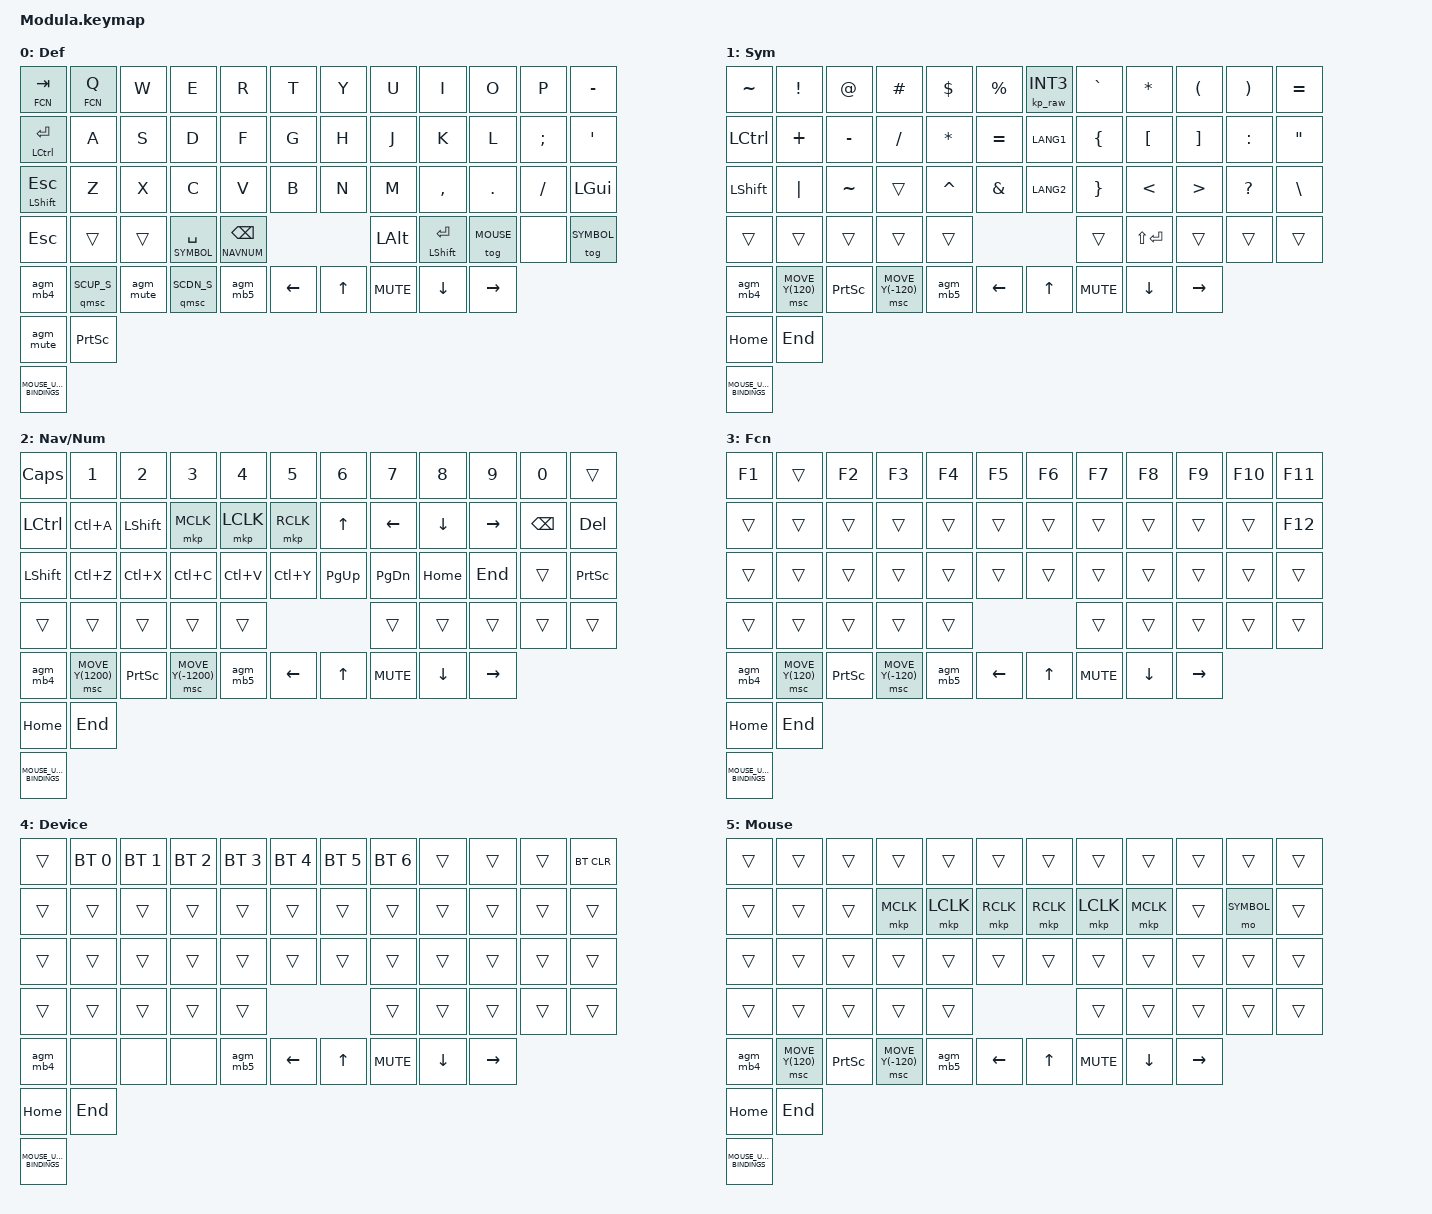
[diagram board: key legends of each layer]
#include <behaviors.dtsi>
#include <behaviors/jp.dtsi>
#include <behaviors/quick_scroll.dtsi>
#include <dt-bindings/zmk/bt.h>
#include <dt-bindings/zmk/keys.h>
#include <dt-bindings/zmk/pointing.h>
#include <dt-bindings/zmk/outputs.h>

#ifdef MODULA_MOUSE_UNIT
#define MODULE_ENCODER_BINDING &mouse_scrl
#define MOUSE_UNIT_BINDINGS &mkp LCLK &mkp RCLK
#else
#define MODULE_ENCODER_BINDING &bri_alt_gui
#define MOUSE_UNIT_BINDINGS
#endif

#define DEFAULT 0
#define SYMBOL 1
#define NAVNUM 2
#define FCN 3
#define DEVICE 4
#define MOUSE 5
#define SCUP_S MOVE_Y(120)
#define SCUP_F MOVE_Y(1200)
#define SCDN_S MOVE_Y(-120)
#define SCDN_F MOVE_Y(-1200)

&mt {
    flavor = "hold-preferred";
};

&lt {
    flavor = "hold-preferred";
};

&qmsc {
    double-tap-ms = <100>;
};

// &msc { 
//     delay-ms = <0>;
//     trigger-period-ms = <100>; // default:16
//     x-input-code = <INPUT_REL_HWHEEL>;
//     y-input-code = <INPUT_REL_WHEEL>;
//     time-to-max-speed-ms = <300>;
//     acceleration-exponent = <0>;
// };

/ {

    // msc_input_listener: msch_input_listener {
    //     compatible = "zmk,input-listener";
    //     device = <&msch>;
    //     // input-processors = 
    // };

    conditional_layers {
        compatible = "zmk,conditional-layers";
        device_layer {
            if-layers = <SYMBOL NAVNUM>;
            then-layer = <DEVICE>;
        };
    };

    combos{
    };

    behaviors {
        msch: msc-hold {
            compatible = "zmk,behavior-input-two-axis";
            #binding-cells = <1>;
            x-input-code = <INPUT_REL_HWHEEL>;
            y-input-code = <INPUT_REL_WHEEL>;
            time-to-max-speed-ms = <300>;
            acceleration-exponent = <0>;
        };
        msc_dt: msc-double-tap {
            compatible = "zmk,behavior-hold-tap";
            #binding-cells = <2>;
            flavor = "hold-preferred";
            tapping-term-ms = <100>;
            quick-tap-ms = <300>;
            bindings = <&msc>, <&msc>;
        };
        // Hold-Tap
        plt: positional_layer_tap {
            compatible = "zmk,behavior-hold-tap";
            #binding-cells = <2>;
            flavor = "hold-preferred";
            tapping-term-ms = <1000>;
            quick-tap-ms = <200>;
            bindings = <&mo>, <&kp>;
            hold-trigger-key-positions = <0>;
        };
        mth: mt-hold-while-undecided {
            compatible = "zmk,behavior-hold-tap";
            #binding-cells = <2>;
            flavor = "hold-preferred";
            hold-while-undecided;
            tapping-term-ms = <200>;
            bindings = <&kp>, <&kp>;
        };
        lth: lt-hold-while-undecided {
            compatible = "zmk,behavior-hold-tap";
            #binding-cells = <2>;
            flavor = "hold-preferred";
            hold-while-undecided;
            tapping-term-ms = <200>;
            bindings = <&mo>, <&kp>;
        };
        mtt: mt-tap-preferred {
            compatible = "zmk,behavior-hold-tap";
            #binding-cells = <2>;
            tapping-term-ms = <150>;
            quick-tap-ms = <0>;
            flavor = "tap-preferred";
            bindings = <&kp>, <&kp>;
        };
        ltt: lt-tap-preferred {
            compatible = "zmk,behavior-hold-tap";
            #binding-cells = <2>;
            flavor = "tap-preferred";
            tapping-term-ms = <200>;
            bindings = <&mo>, <&kp>;
        };
        // Encoders
        mouse_scrl: mouse_wheel_scrl {
            compatible = "zmk,behavior-sensor-rotate";
            #sensor-binding-cells = <0>;
            bindings = <&msc MOVE_UP>, <&msc MOVE_DOWN>;
            tap-ms = <20>;
        };
        vol_up_down: volume-up-down {
            compatible = "zmk,behavior-sensor-rotate";
            #sensor-binding-cells = <0>;
            bindings = <&kp C_VOL_UP>, <&kp C_VOL_DN>;
        };
        bri_up_down: brightness-up-down {
            compatible = "zmk,behavior-sensor-rotate";
            #sensor-binding-cells = <0>; 
            bindings = <&kp C_BRI_INC>, <&kp C_BRI_DEC>;
        };
        agm_mute: alt-gui-mute {
            compatible = "modula,behavior-alt-gui-morph";
            #binding-cells = <0>;
            bindings = <&kp C_MUTE>, <&kp LC(TAB)>, <&kp 0>;
        };
        agm_vol_up: alt-gui-volume-up {
            compatible = "modula,behavior-alt-gui-morph";
            #binding-cells = <0>;
            bindings = <&kp C_VOL_UP>, <&kp TAB>, <&kp RIGHT>;
        };
        agm_vol_down: alt-gui-volume-down {
            compatible = "modula,behavior-alt-gui-morph";
            #binding-cells = <0>;
            bindings = <&kp C_VOL_DN>, <&kp LS(TAB)>, <&kp LEFT>;
        };
        agm_bri_up: alt-gui-brightness-up {
            compatible = "modula,behavior-alt-gui-morph";
            #binding-cells = <0>;
            bindings = <&kp C_BRI_INC>, <&kp TAB>, <&kp RIGHT>;
        };
        agm_bri_down: alt-gui-brightness-down {
            compatible = "modula,behavior-alt-gui-morph";
            #binding-cells = <0>;
            bindings = <&kp C_BRI_DEC>, <&kp LS(TAB)>, <&kp LEFT>;
        };
        agm_mb5: alt-gui-mb5 {
            compatible = "modula,behavior-alt-gui-morph";
            #binding-cells = <0>;
            bindings = <&mkp MB5>, <&kp TAB>, <&kp RIGHT>;
        };
        agm_mb4: alt-gui-mb4 {
            compatible = "modula,behavior-alt-gui-morph";
            #binding-cells = <0>;
            bindings = <&mkp MB4>, <&kp LS(TAB)>, <&kp LEFT>;
        };

        vol_alt_gui: volume-alt-gui {
            compatible = "zmk,behavior-sensor-rotate";
            #sensor-binding-cells = <0>;
            bindings = <&agm_vol_up>, <&agm_vol_down>;
            tap-ms = <10>;
        };
        bri_alt_gui: brightness-alt-gui {
            compatible = "zmk,behavior-sensor-rotate";
            #sensor-binding-cells = <0>;
            bindings = <&agm_bri_up>, <&agm_bri_down>;
            tap-ms = <10>;
        };
    };

// arrow direction < ^ _ v >
	keymap {
		compatible = "zmk,keymap";
		default_layer {
			label="Def";
			bindings = <
&lth FCN TAB    &plt FCN Q    &kp W         &kp E     &kp R             &kp T                   &kp Y       &kp U           &kp I       &kp O       &kp P        &kp MINUS
&mth LCTRL RET  &kp A         &kp S         &kp D     &kp F             &kp G                   &kp H       &kp J           &kp K       &kp L       &kp SEMI     &kp SQT
&mth LSHIFT ESC &kp Z         &kp X         &kp C     &kp V             &kp B                   &kp N       &kp M           &kp COMMA   &kp DOT     &kp SLASH    &kp LGUI
&kp  ESC        &trans        &trans        &lth SYMBOL SPACE &lth NAVNUM BSPC                  &kp LALT    &mt LSHFT RET               &tog MOUSE  &none &tog SYMBOL
&agm_mb4  &qmsc SCUP_S &agm_mute  &qmsc SCDN_S   &agm_mb5            &kp LEFT    &kp UP          &kp C_MUTE  &kp DOWN   &kp RIGHT
&agm_mute  &kp PSCRN
MOUSE_UNIT_BINDINGS
			>;
            sensor-bindings = <MODULE_ENCODER_BINDING &vol_alt_gui>;
		};
		
		symbol_layer {
			label="Sym";
			bindings = <
&kp TILDE &kp EXCL  &kp AT     &kp HASH     &kp DLLR         &kp PRCNT        &kp_raw INT3 &kp GRAVE  &kp ASTRK  &kp LPAR  &kp RPAR  &kp EQUAL
&kp LCTRL &kp PLUS  &kp MINUS  &kp SLASH    &kp ASTRK        &kp EQUAL        &kp LANG1  &kp LBRC   &kp LBKT   &kp RBKT  &kp COLON &kp DQT
&kp LSHIFT &kp PIPE &kp TILDE  &trans       &kp CARET        &kp AMPS         &kp LANG2  &kp RBRC   &kp LT     &kp GT    &kp QMARK &kp BSLH
&trans       &trans       &trans                        &trans              &trans              &trans       &kp LS(RET)                 &trans       &trans       &trans 
&agm_mb4  &msc MOVE_Y(120)   &kp PSCRN  &msc MOVE_Y(-120)   &agm_mb5            &kp LEFT    &kp UP          &kp C_MUTE  &kp DOWN   &kp RIGHT
&kp HOME &kp END
MOUSE_UNIT_BINDINGS
			>;
            sensor-bindings = <MODULE_ENCODER_BINDING &vol_alt_gui>;
		};
		
		navnum_layer {
			label="Nav/Num";
			bindings = <
&kp CAPSLOCK &kp N1    &kp N2     &kp N3    &kp N4    &kp N5    &kp N6    &kp N7    &kp N8   &kp N9    &kp N0   &trans
&kp LCTRL    &kp LC(A) &kp LSHIFT &mkp MCLK &mkp LCLK &mkp RCLK &kp UP    &kp LEFT  &kp DOWN &kp RIGHT &kp BSPC &kp DEL
&kp LSHIFT   &kp LC(Z) &kp LC(X)  &kp LC(C) &kp LC(V) &kp LC(Y) &kp PG_UP &kp PG_DN &kp HOME &kp END   &trans   &kp PSCRN
&trans       &trans    &trans               &trans    &trans    &trans    &trans             &trans    &trans   &trans
&agm_mb4  &msc MOVE_Y(1200)   &kp PSCRN  &msc MOVE_Y(-1200)   &agm_mb5            &kp LEFT    &kp UP          &kp C_MUTE  &kp DOWN   &kp RIGHT
&kp HOME &kp END
MOUSE_UNIT_BINDINGS
			>;
            sensor-bindings = <MODULE_ENCODER_BINDING &vol_alt_gui>;
		};
		
		function_layer {
			label="Fcn";
			bindings = <
&kp F1 &trans &kp F2 &kp F3 &kp F4 &kp F5 &kp F6 &kp F7 &kp F8 &kp F9 &kp F10 &kp F11
&trans &trans &trans &trans &trans &trans &trans &trans &trans &trans &trans  &kp F12
&trans &trans &trans &trans &trans &trans &trans &trans &trans &trans &trans  &trans
&trans &trans &trans        &trans &trans &trans &trans        &trans &trans  &trans
&agm_mb4  &msc MOVE_Y(120)   &kp PSCRN  &msc MOVE_Y(-120)   &agm_mb5            &kp LEFT    &kp UP          &kp C_MUTE  &kp DOWN   &kp RIGHT
&kp HOME &kp END
MOUSE_UNIT_BINDINGS
			>;
            sensor-bindings = <MODULE_ENCODER_BINDING &vol_alt_gui>;
		};
		
		device_layer {
			label="Device";
			bindings = <
&trans            &bt BT_SEL 0     &bt BT_SEL 1     &bt BT_SEL 2     &bt BT_SEL 3     &bt BT_SEL 4         &bt BT_SEL 5      &bt BT_SEL 6     &trans           &trans           &trans           &bt BT_CLR
&trans            &trans           &trans           &trans           &trans           &trans               &trans            &trans           &trans           &trans           &trans           &trans
&trans            &trans           &trans           &trans           &trans           &trans               &trans            &trans           &trans           &trans           &trans           &trans
&trans            &trans           &trans                            &trans           &trans               &trans            &trans                            &trans           &trans           &trans
&agm_mb4  &none   &none  &none   &agm_mb5            &kp LEFT    &kp UP          &kp C_MUTE  &kp DOWN   &kp RIGHT
&kp HOME &kp END
MOUSE_UNIT_BINDINGS
			>;
            sensor-bindings = <MODULE_ENCODER_BINDING &vol_alt_gui>;
		};

        mouse_layer {
			label="Mouse";
			bindings = <
&trans  &trans  &trans  &trans  &trans  &trans                              &trans  &trans  &trans  &trans  &trans  &trans
&trans  &trans  &trans  &mkp MCLK  &mkp LCLK  &mkp RCLK                     &mkp RCLK  &mkp LCLK  &mkp MCLK &trans  &mo SYMBOL &trans
&trans  &trans  &trans  &trans  &trans  &trans                              &trans  &trans  &trans  &trans  &trans  &trans
&trans  &trans  &trans          &trans  &trans                              &trans  &trans          &trans  &trans  &trans
&agm_mb4  &msc MOVE_Y(120)   &kp PSCRN  &msc MOVE_Y(-120)   &agm_mb5            &kp LEFT    &kp UP          &kp C_MUTE  &kp DOWN   &kp RIGHT
&kp HOME &kp END
MOUSE_UNIT_BINDINGS
			>;
            sensor-bindings = <MODULE_ENCODER_BINDING &vol_alt_gui>;
		};
	};
};
